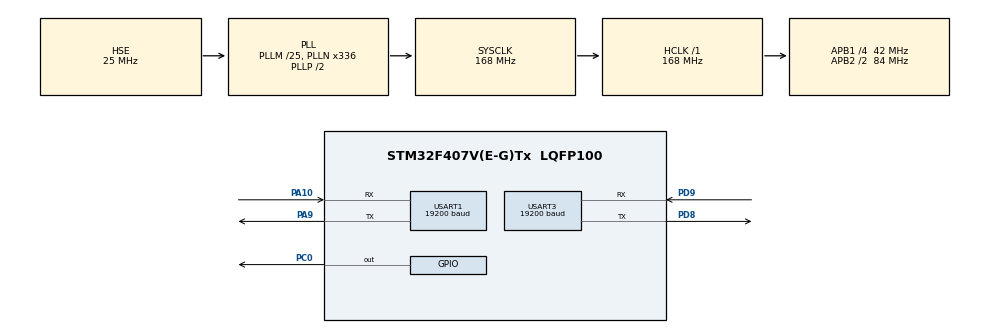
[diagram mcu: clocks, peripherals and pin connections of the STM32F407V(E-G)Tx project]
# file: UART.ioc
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Mcu.Family=STM32F4
Mcu.Name=STM32F407V(E-G)Tx
Mcu.Package=LQFP100
NVIC.PriorityGroup=NVIC_PRIORITYGROUP_3
NVIC.USART1_IRQn=true\:1\:1\:true\:false\:true\:true\:true
NVIC.USART3_IRQn=true\:0\:0\:false\:false\:true\:true\:true
PA10.GPIO_ModeDefaultPP=GPIO_MODE_AF_OD
PA10.GPIO_PuPd=GPIO_PULLUP
PA10.Mode=Asynchronous
PA10.Signal=USART1_RX
PA13.Mode=Serial_Wire
PA13.Signal=SYS_JTMS-SWDIO
PA14.Mode=Serial_Wire
PA14.Signal=SYS_JTCK-SWCLK
PA9.GPIO_ModeDefaultPP=GPIO_MODE_AF_OD
PA9.GPIO_PuPd=GPIO_PULLUP
PA9.Mode=Asynchronous
PA9.Signal=USART1_TX
PC0.GPIO_ModeDefaultOutputPP=GPIO_MODE_OUTPUT_OD
PC0.Signal=GPIO_Output
PD8.GPIO_ModeDefaultPP=GPIO_MODE_AF_OD
PD8.Mode=Asynchronous
PD8.Signal=USART3_TX
PD9.GPIO_ModeDefaultPP=GPIO_MODE_AF_OD
PD9.Mode=Asynchronous
PD9.Signal=USART3_RX
PH0-OSC_IN.Mode=HSE-External-Oscillator
PH0-OSC_IN.Signal=RCC_OSC_IN
PH1-OSC_OUT.Mode=HSE-External-Oscillator
PH1-OSC_OUT.Signal=RCC_OSC_OUT
ProjectManager.HeapSize=0x200
ProjectManager.StackSize=0x400
ProjectManager.TargetToolchain=MDK-ARM V5.27
RCC.48MHZClocksFreq_Value=84000000
RCC.AHBFreq_Value=168000000
RCC.APB1CLKDivider=RCC_HCLK_DIV4
RCC.APB1Freq_Value=42000000
RCC.APB1TimFreq_Value=84000000
RCC.APB2CLKDivider=RCC_HCLK_DIV2
RCC.APB2Freq_Value=84000000
RCC.APB2TimFreq_Value=168000000
RCC.CortexFreq_Value=168000000
RCC.HCLKFreq_Value=168000000
RCC.HSE_VALUE=25000000
RCC.HSI_VALUE=16000000
RCC.LSE_VALUE=32768
RCC.PLLM=25
RCC.PLLN=336
RCC.PLLSourceVirtual=RCC_PLLSOURCE_HSE
RCC.SYSCLKFreq_VALUE=168000000
RCC.SYSCLKSource=RCC_SYSCLKSOURCE_PLLCLK
RCC.VCOOutputFreq_Value=336000000
USART1.BaudRate=19200
USART1.VirtualMode=VM_ASYNC
USART3.BaudRate=19200
USART3.VirtualMode=VM_ASYNC
board=custom

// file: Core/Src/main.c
/* USER CODE BEGIN Header */
/**
  ******************************************************************************
  * @file           : main.c
  * @brief          : Main program body
  ******************************************************************************
  * @attention
  *
  * <h2><center>&copy; Copyright (c) 2021 STMicroelectronics.
  * All rights reserved.</center></h2>
  *
  * This software component is licensed by ST under BSD 3-Clause license,
  * the "License"; You may not use this file except in compliance with the
  * License. You may obtain a copy of the License at:
  *                        opensource.org/licenses/BSD-3-Clause
  *
  ******************************************************************************
  */
/* USER CODE END Header */
#include "main.h"

/* USER CODE BEGIN Includes */
	uint8_t aTxStartMessages[] = "COPY";
	uint8_t aRxBuffer[20];
	uint8_t flag;
	uint8_t temp[9]={0X99,0X06,0X46,0XA8,0X5D,0XB0,0X9A,0X4E,0XD1};
/* USER CODE END Includes */

UART_HandleTypeDef huart1;
UART_HandleTypeDef huart3;

void SystemClock_Config(void);
static void MX_GPIO_Init(void);
static void MX_USART1_UART_Init(void);
static void MX_USART3_UART_Init(void);

int main(void)
{
  /* USER CODE BEGIN 1 */
	int i=0;
  /* USER CODE END 1 */

  /* MCU Configuration--------------------------------------------------------*/

  /* Reset of all peripherals, Initializes the Flash interface and the Systick. */
  HAL_Init();

  /* Configure the system clock */
  SystemClock_Config();

  /* Initialize all configured peripherals */
  MX_GPIO_Init();
  MX_USART1_UART_Init();
  MX_USART3_UART_Init();
  /* USER CODE BEGIN 2 */

//	HAL_UART_Receive_IT(&huart1,&temp,1);
//	HAL_UART_Receive(&huart1,aRxBuffer,1,10);
  /* USER CODE END 2 */

  /* Infinite loop */
  /* USER CODE BEGIN WHILE */
  while (1)
  {

	//	if(HAL_UART_Receive(&huart1,&temp,1,0xFF)==HAL_OK)
		for(i=0;i<9;i++)
		{
			HAL_UART_Transmit(&huart1,&temp[i],1,0xFF);
			while((USART1->SR&0X40)==0);
		}
		HAL_Delay(4000);

    /* USER CODE END WHILE */

  }
}

void SystemClock_Config(void)
{
  RCC_OscInitTypeDef RCC_OscInitStruct = {0};
  RCC_ClkInitTypeDef RCC_ClkInitStruct = {0};

  /** Configure the main internal regulator output voltage
  */
  __HAL_RCC_PWR_CLK_ENABLE();
  __HAL_PWR_VOLTAGESCALING_CONFIG(PWR_REGULATOR_VOLTAGE_SCALE1);
  /** Initializes the RCC Oscillators according to the specified parameters
  * in the RCC_OscInitTypeDef structure.
  */
  RCC_OscInitStruct.OscillatorType = RCC_OSCILLATORTYPE_HSE;
  RCC_OscInitStruct.HSEState = RCC_HSE_ON;
  RCC_OscInitStruct.PLL.PLLState = RCC_PLL_ON;
  RCC_OscInitStruct.PLL.PLLSource = RCC_PLLSOURCE_HSE;
  RCC_OscInitStruct.PLL.PLLM = 25;
  RCC_OscInitStruct.PLL.PLLN = 336;
  RCC_OscInitStruct.PLL.PLLP = RCC_PLLP_DIV2;
  RCC_OscInitStruct.PLL.PLLQ = 4;
  if (HAL_RCC_OscConfig(&RCC_OscInitStruct) != HAL_OK)
  {
    Error_Handler();
  }
  /** Initializes the CPU, AHB and APB buses clocks
  */
  RCC_ClkInitStruct.ClockType = RCC_CLOCKTYPE_HCLK|RCC_CLOCKTYPE_SYSCLK
                              |RCC_CLOCKTYPE_PCLK1|RCC_CLOCKTYPE_PCLK2;
  RCC_ClkInitStruct.SYSCLKSource = RCC_SYSCLKSOURCE_PLLCLK;
  RCC_ClkInitStruct.AHBCLKDivider = RCC_SYSCLK_DIV1;
  RCC_ClkInitStruct.APB1CLKDivider = RCC_HCLK_DIV4;
  RCC_ClkInitStruct.APB2CLKDivider = RCC_HCLK_DIV2;

  if (HAL_RCC_ClockConfig(&RCC_ClkInitStruct, FLASH_LATENCY_5) != HAL_OK)
  {
    Error_Handler();
  }
}

static void MX_USART1_UART_Init(void)
{

  huart1.Instance = USART1;
  huart1.Init.BaudRate = 19200;
  huart1.Init.WordLength = UART_WORDLENGTH_8B;
  huart1.Init.StopBits = UART_STOPBITS_1;
  huart1.Init.Parity = UART_PARITY_NONE;
  huart1.Init.Mode = UART_MODE_TX_RX;
  huart1.Init.HwFlowCtl = UART_HWCONTROL_NONE;
  huart1.Init.OverSampling = UART_OVERSAMPLING_16;
  if (HAL_UART_Init(&huart1) != HAL_OK)
  {
    Error_Handler();
  }

}

static void MX_USART3_UART_Init(void)
{

  huart3.Instance = USART3;
  huart3.Init.BaudRate = 19200;
  huart3.Init.WordLength = UART_WORDLENGTH_8B;
  huart3.Init.StopBits = UART_STOPBITS_1;
  huart3.Init.Parity = UART_PARITY_NONE;
  huart3.Init.Mode = UART_MODE_TX_RX;
  huart3.Init.HwFlowCtl = UART_HWCONTROL_NONE;
  huart3.Init.OverSampling = UART_OVERSAMPLING_16;
  if (HAL_UART_Init(&huart3) != HAL_OK)
  {
    Error_Handler();
  }

}

static void MX_GPIO_Init(void)
{
  GPIO_InitTypeDef GPIO_InitStruct = {0};

  /* GPIO Ports Clock Enable */
  __HAL_RCC_GPIOH_CLK_ENABLE();
  __HAL_RCC_GPIOC_CLK_ENABLE();
  __HAL_RCC_GPIOD_CLK_ENABLE();
  __HAL_RCC_GPIOA_CLK_ENABLE();

  /*Configure GPIO pin Output Level */
  HAL_GPIO_WritePin(GPIOC, GPIO_PIN_0, GPIO_PIN_RESET);

  /*Configure GPIO pin : PC0 */
  GPIO_InitStruct.Pin = GPIO_PIN_0;
  GPIO_InitStruct.Mode = GPIO_MODE_OUTPUT_OD;
  GPIO_InitStruct.Pull = GPIO_NOPULL;
  GPIO_InitStruct.Speed = GPIO_SPEED_FREQ_LOW;
  HAL_GPIO_Init(GPIOC, &GPIO_InitStruct);

}

/* USER CODE BEGIN 4 */
void HAL_UART_RxCpltCallback(UART_HandleTypeDef *huart)
{
	UNUSED(huart);
//	HAL_UART_Transmit(&huart1,(uint8_t*)aRxBuffer,1,0xFF);//(uint8_t*)aRxBuffer??????,10??????,0xFFFF?????
	//HAL_UART_Transmit_IT(&huart1,&temp,1);
//	HAL_UART_Receive_IT(&huart1,&temp,1);

}
/* USER CODE END 4 */

void Error_Handler(void)
{
}

/************************ (C) COPYRIGHT STMicroelectronics *****END OF FILE****/
